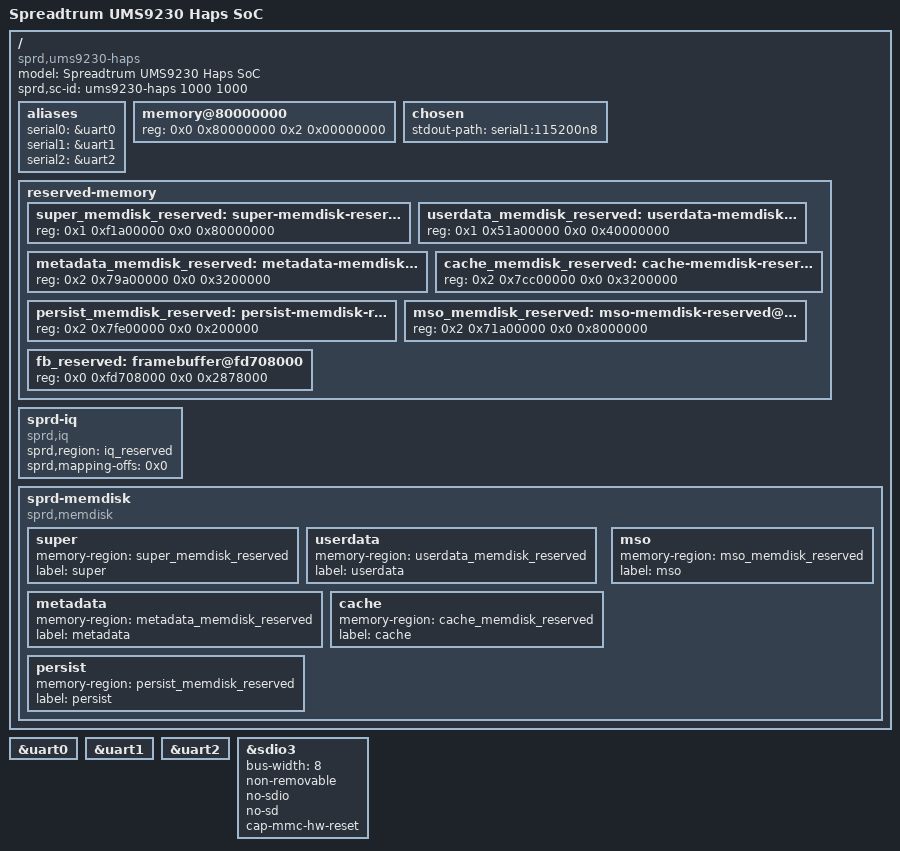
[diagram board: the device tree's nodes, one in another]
// SPDX-License-Identifier: GPL-2.0-only
/*
 * Unisoc Qogirl6 platform DTS file
 *
 * Copyright (C) 2020, Unisoc Inc.
 */

/dts-v1/;

#include "ums9230-haps.dtsi"
#include "ums9230-haps-mach.dtsi"
#include "ums9230-haps-modem.dtsi"

/ {
	model = "Spreadtrum UMS9230 Haps SoC";

	compatible = "sprd,ums9230-haps";

	sprd,sc-id = "ums9230-haps 1000 1000";

	aliases {
		serial0 = &uart0;
		serial1 = &uart1;
		serial2 = &uart2;
	};

	memory@80000000 {
		device_type = "memory";
		reg = <0x0 0x80000000 0x2 0x00000000>;
	};

	chosen: chosen {
		stdout-path = "serial1:115200n8";
	};

	reserved-memory {
		#address-cells = <2>;
		#size-cells = <2>;
		ranges;

		super_memdisk_reserved: super-memdisk-reserved@1f1a00000{
			reg = <0x1 0xf1a00000 0x0 0x80000000>;  /* system 2G */
		};

		userdata_memdisk_reserved: userdata-memdisk-reserved@151a00000{
			reg = <0x1 0x51a00000 0x0 0x40000000>; /* userdata 1G */
		};

		metadata_memdisk_reserved: metadata-memdisk-reserved@279a00000{
			reg = <0x2 0x79a00000 0x0 0x3200000>; /* metadata 50M */
		};

		cache_memdisk_reserved: cache-memdisk-reserved@27cc00000{
			reg = <0x2 0x7cc00000 0x0 0x3200000>; /* cache 50M */
		};

		persist_memdisk_reserved: persist-memdisk-reserved@27fe00000{
			reg = <0x2 0x7fe00000 0x0 0x200000>; /* persist 2M */
		};

		mso_memdisk_reserved: mso-memdisk-reserved@271a00000{
			reg = <0x2 0x71a00000 0x0 0x8000000>; /* mso 128M */
		};

		fb_reserved: framebuffer@fd708000 {
			reg = <0x0 0xfd708000 0x0 0x2878000>;
		};
	};

	sprd-iq {
		compatible = "sprd,iq";
		sprd,region = <&iq_reserved>;
		sprd,mapping-offs = <0x0>;
	};

	sprd-memdisk {
		compatible = "sprd,memdisk";

		super {
			memory-region = <&super_memdisk_reserved>;
			label = "super";
		};

		userdata {
			memory-region = <&userdata_memdisk_reserved>;
			label = "userdata";
		};

		metadata {
			memory-region = <&metadata_memdisk_reserved>;
			label = "metadata";
		};

		cache {
			memory-region = <&cache_memdisk_reserved>;
			label = "cache";
		};

		persist {
			memory-region = <&persist_memdisk_reserved>;
			label = "persist";
		};

		mso {
			memory-region = <&mso_memdisk_reserved>;
			label = "mso";
		};
	};
};

&uart0 {
	status = "okay";
};

&uart1 {
	status = "okay";
};

&uart2 {
	status = "okay";
};

&sdio3 {
	bus-width = <8>;
	non-removable;
	no-sdio;
	no-sd;
	cap-mmc-hw-reset;
	status = "okay";
};
